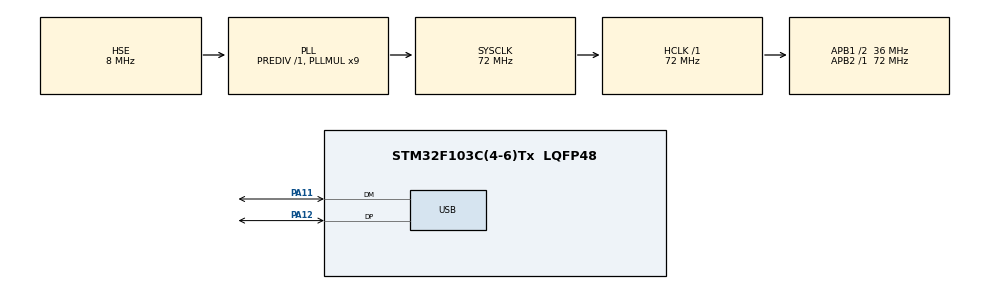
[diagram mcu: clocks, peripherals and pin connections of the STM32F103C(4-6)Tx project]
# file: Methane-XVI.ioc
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Mcu.Family=STM32F1
Mcu.Name=STM32F103C(4-6)Tx
Mcu.Package=LQFP48
NVIC.PriorityGroup=NVIC_PRIORITYGROUP_4
NVIC.USB_LP_CAN1_RX0_IRQn=true\:0\:0\:false\:false\:true\:false\:true\:true
PA11.Mode=Device
PA11.Signal=USB_DM
PA12.Mode=Device
PA12.Signal=USB_DP
PA13.Mode=Serial_Wire
PA13.Signal=SYS_JTMS-SWDIO
PA14.Mode=Serial_Wire
PA14.Signal=SYS_JTCK-SWCLK
PD0-OSC_IN.Mode=HSE-External-Oscillator
PD0-OSC_IN.Signal=RCC_OSC_IN
PD1-OSC_OUT.Mode=HSE-External-Oscillator
PD1-OSC_OUT.Signal=RCC_OSC_OUT
ProjectManager.HeapSize=0x400
ProjectManager.StackSize=0x200
ProjectManager.TargetToolchain=MDK-ARM V5
RCC.AHBFreq_Value=72000000
RCC.APB1CLKDivider=RCC_HCLK_DIV2
RCC.APB1Freq_Value=36000000
RCC.APB1TimFreq_Value=72000000
RCC.APB2Freq_Value=72000000
RCC.APB2TimFreq_Value=72000000
RCC.HCLKFreq_Value=72000000
RCC.PLLMUL=RCC_PLL_MUL9
RCC.SYSCLKFreq_VALUE=72000000
RCC.SYSCLKSource=RCC_SYSCLKSOURCE_PLLCLK
RCC.USBFreq_Value=48000000
RCC.USBPrescaler=RCC_USBCLKSOURCE_PLL_DIV1_5
USB_DEVICE.CLASS_NAME_FS=CUSTOM_HID
USB_DEVICE.MANUFACTURER_STRING=Light&Electricity
USB_DEVICE.PID_CUSTOMHID_FS=22335
USB_DEVICE.PRODUCT_STRING_CUSTOMHID_FS=Methane-XVI
USB_DEVICE.USBD_CUSTOMHID_OUTREPORT_BUF_SIZE=64
USB_DEVICE.VirtualMode=CustomHid
USB_DEVICE.VirtualModeFS=Custom_Hid_FS
VP_USB_DEVICE_VS_USB_DEVICE_CUSTOM_HID_FS.Mode=CUSTOM_HID_FS
board=custom

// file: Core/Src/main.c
/* USER CODE BEGIN Header */
/**
  ******************************************************************************
  * @file           : main.c
  * @brief          : Methane-XVI Firmware V2.2
  ******************************************************************************
  * @attention
  *
  * Copyright (c) 2023 STMicroelectronics.
  * All rights reserved.
  *
  * This software is licensed under terms that can be found in the LICENSE file
  * in the root directory of this software component.
  * If no LICENSE file comes with this software, it is provided AS-IS.
  *
  ******************************************************************************
  */
/* USER CODE END Header */
#include "main.h"
#include "usb_device.h"

/* USER CODE BEGIN Includes */
#include "usbd_customhid.h"
#include "LL_convert.h"
/* USER CODE END Includes */

/* USER CODE BEGIN PV */
extern USBD_HandleTypeDef hUsbDeviceFS;

extern uint8_t ifReceiving;//接收数据标志位
extern uint8_t savePlace;//存储位置
extern uint8_t saveMid;//存储中位标志

uint8_t USB_TX_BUF[64];//自定义HID发送缓冲
uint8_t USB_RX_BUF[64];//自定义HID接收缓冲

uint8_t KeyBrd_if_send = 0;//键盘报文是否发送
uint8_t Mouse_if_send = 0;//鼠标报文是否发送
uint8_t Point_if_send = 0;//指针报文是否发送
uint8_t Vol_if_send = 0;//媒体报文是否发送

uint8_t KeyBrd_data[KB_len] = {1,0,0,0};//编号1,功能键,保留0,其他按键
//功能键:bit7-bit0分别为为右win alt shift ctrl,左win alt shift ctrl

uint8_t Mouse_data[5] = {2,0,0,0,0};//编号2,功能键,x,y,滚轮
//功能键:bit0为左键,bit1为右键,bit2为中键,bit6为x是否溢出,bit7为y是否溢出

uint8_t Point_data[7] = {3,0x10,1,0,0,0,0};//编号3,功能键,id,x_L,x_H,y_L,y_H
//功能键:bit0为Tip Switch,bit1为Barrel Switch,bit2为Invert,bit3为Eraser Switch,bit4为In Range

uint8_t Vol_data[2] = {4,0};//编号4,功能键
//功能键:bit0音量加,bit1音量减,bit2静音,bit3播放暂停

/* USER CODE END PV */

void SystemClock_Config(void);
static void MX_GPIO_Init(void);

int main(void)
{

  /* MCU Configuration--------------------------------------------------------*/

  /* Reset of all peripherals, Initializes the Flash interface and the Systick. */
  HAL_Init();

  /* Configure the system clock */
  SystemClock_Config();

  /* USER CODE BEGIN SysInit */
	LL_Init();
  /* USER CODE END SysInit */

  /* Initialize all configured peripherals */
//  MX_GPIO_Init();
  MX_USB_DEVICE_Init();

  /* Infinite loop */
  while (1)
  {
    /* USER CODE BEGIN 3 */
	  LL_Loop();
	  if(ifReceiving) continue;//若USB正在接收数据则跳过HID发送
	  if(savePlace){//需要更新参数
		  Update_para(savePlace - 1);
		  savePlace = 0;
//		  Light_handle(4,100);
		  continue;
	  }
	  if(saveMid){//需要更新摇杆中位等
		  Ana_mid_ctrl(1);//存储摇杆中位等
		  saveMid = 0;
		  continue;
	  }

	  if(KeyBrd_if_send){
		  USBD_HID_SendReport(&hUsbDeviceFS,(uint8_t*)&KeyBrd_data,sizeof(KeyBrd_data));
		  HAL_Delay(8);
	  }
	  if(Mouse_if_send){
		  USBD_HID_SendReport(&hUsbDeviceFS,(uint8_t*)&Mouse_data,sizeof(Mouse_data));
		  HAL_Delay(8);
	  }
	  if(Point_if_send){
		  USBD_HID_SendReport(&hUsbDeviceFS,(uint8_t*)&Point_data,sizeof(Point_data));
		  HAL_Delay(8);
	  }
	  if(Vol_if_send){
		  USBD_HID_SendReport(&hUsbDeviceFS,(uint8_t*)&Vol_data,sizeof(Vol_data));
		  HAL_Delay(8);
	  }
  }
  /* USER CODE END 3 */
}

void SystemClock_Config(void)
{
  RCC_OscInitTypeDef RCC_OscInitStruct = {0};
  RCC_ClkInitTypeDef RCC_ClkInitStruct = {0};
  RCC_PeriphCLKInitTypeDef PeriphClkInit = {0};

  /** Initializes the RCC Oscillators according to the specified parameters
  * in the RCC_OscInitTypeDef structure.
  */
  RCC_OscInitStruct.OscillatorType = RCC_OSCILLATORTYPE_HSE;
  RCC_OscInitStruct.HSEState = RCC_HSE_ON;
  RCC_OscInitStruct.HSEPredivValue = RCC_HSE_PREDIV_DIV1;
  RCC_OscInitStruct.HSIState = RCC_HSI_ON;
  RCC_OscInitStruct.PLL.PLLState = RCC_PLL_ON;
  RCC_OscInitStruct.PLL.PLLSource = RCC_PLLSOURCE_HSE;
  RCC_OscInitStruct.PLL.PLLMUL = RCC_PLL_MUL9;
  if (HAL_RCC_OscConfig(&RCC_OscInitStruct) != HAL_OK)
  {
    Error_Handler();
  }

  /** Initializes the CPU, AHB and APB buses clocks
  */
  RCC_ClkInitStruct.ClockType = RCC_CLOCKTYPE_HCLK|RCC_CLOCKTYPE_SYSCLK
                              |RCC_CLOCKTYPE_PCLK1|RCC_CLOCKTYPE_PCLK2;
  RCC_ClkInitStruct.SYSCLKSource = RCC_SYSCLKSOURCE_PLLCLK;
  RCC_ClkInitStruct.AHBCLKDivider = RCC_SYSCLK_DIV1;
  RCC_ClkInitStruct.APB1CLKDivider = RCC_HCLK_DIV2;
  RCC_ClkInitStruct.APB2CLKDivider = RCC_HCLK_DIV1;

  if (HAL_RCC_ClockConfig(&RCC_ClkInitStruct, FLASH_LATENCY_2) != HAL_OK)
  {
    Error_Handler();
  }
  PeriphClkInit.PeriphClockSelection = RCC_PERIPHCLK_USB;
  PeriphClkInit.UsbClockSelection = RCC_USBCLKSOURCE_PLL_DIV1_5;
  if (HAL_RCCEx_PeriphCLKConfig(&PeriphClkInit) != HAL_OK)
  {
    Error_Handler();
  }
}

static void MX_GPIO_Init(void)
{

  /* GPIO Ports Clock Enable */
  __HAL_RCC_GPIOD_CLK_ENABLE();
  __HAL_RCC_GPIOA_CLK_ENABLE();

}

void Error_Handler(void)
{
  __disable_irq();
  while (1)
  {
  }
}
